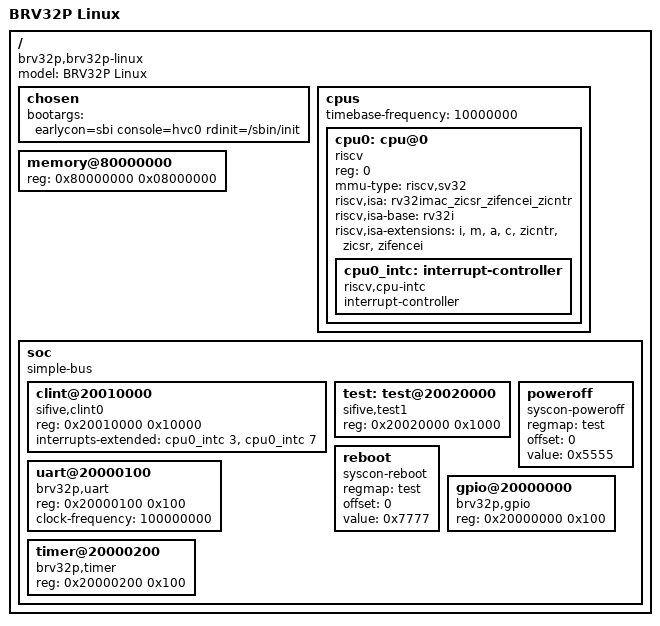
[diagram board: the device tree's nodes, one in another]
// SPDX-License-Identifier: GPL-2.0-or-later
/*
 * The brv32p-linux machine: the BRV32P SoC plus the smallest set of additions Linux needs
 * (ACLINT timer and software interrupt, 128 MiB of RAM at 0x80000000). See docs/linux.md.
 */
/dts-v1/;

/ {
	#address-cells = <1>;
	#size-cells = <1>;
	compatible = "brv32p,brv32p-linux";
	model = "BRV32P Linux";

	chosen {
		bootargs = "earlycon=sbi console=hvc0 rdinit=/sbin/init";
	};

	cpus {
		#address-cells = <1>;
		#size-cells = <0>;
		timebase-frequency = <10000000>;

		cpu0: cpu@0 {
			device_type = "cpu";
			compatible = "riscv";
			reg = <0>;
			status = "okay";
			mmu-type = "riscv,sv32";
			riscv,isa = "rv32imac_zicsr_zifencei_zicntr";
			riscv,isa-base = "rv32i";
			riscv,isa-extensions = "i", "m", "a", "c", "zicntr", "zicsr", "zifencei";

			cpu0_intc: interrupt-controller {
				#interrupt-cells = <1>;
				compatible = "riscv,cpu-intc";
				interrupt-controller;
			};
		};
	};

	memory@80000000 {
		device_type = "memory";
		reg = <0x80000000 0x08000000>;
	};

	soc {
		#address-cells = <1>;
		#size-cells = <1>;
		compatible = "simple-bus";
		ranges;

		clint@20010000 {
			compatible = "sifive,clint0", "riscv,clint0";
			reg = <0x20010000 0x10000>;
			interrupts-extended = <&cpu0_intc 3>, <&cpu0_intc 7>;
		};

		/* The power-off register: a finisher of the QEMU machine, not part of the RTL */
		test: test@20020000 {
			compatible = "sifive,test1", "sifive,test0", "syscon";
			reg = <0x20020000 0x1000>;
		};

		poweroff {
			compatible = "syscon-poweroff";
			regmap = <&test>;
			offset = <0>;
			value = <0x5555>;
		};

		reboot {
			compatible = "syscon-reboot";
			regmap = <&test>;
			offset = <0>;
			value = <0x7777>;
		};

		uart@20000100 {
			compatible = "brv32p,uart";
			reg = <0x20000100 0x100>;
			clock-frequency = <100000000>;
		};

		gpio@20000000 {
			compatible = "brv32p,gpio";
			reg = <0x20000000 0x100>;
		};

		timer@20000200 {
			compatible = "brv32p,timer";
			reg = <0x20000200 0x100>;
		};
	};
};
